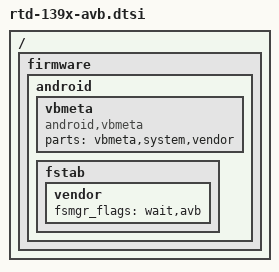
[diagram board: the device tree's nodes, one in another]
/ {
	firmware {
		android {
			vbmeta {
				compatible = "android,vbmeta";
				parts = "vbmeta,system,vendor";
			};
			fstab {
				/delete-node/ system;
				vendor {
					fsmgr_flags = "wait,avb";
				};
			};
		};
	};
};

